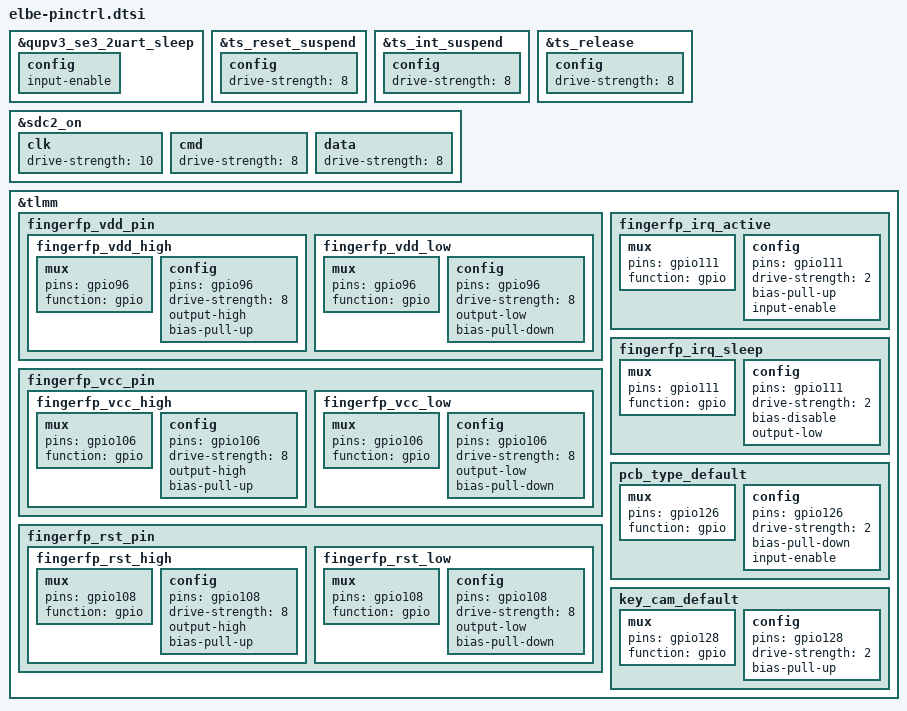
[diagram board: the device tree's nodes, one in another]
&qupv3_se3_2uart_sleep {
	config {
		input-enable;
	};
};

&ts_reset_suspend {
	config {
		drive-strength = <8>;
	};
};

&ts_int_suspend {
	config {
		drive-strength = <8>;
	};
};

&ts_release {
	config {
		drive-strength = <8>;
		/delete-property/ bias-disable;
	};
};

&sdc2_on {
	clk {
		drive-strength = <10>;
	};

	cmd {
		drive-strength = <8>;
	};

	data {
		drive-strength = <8>;
	};
};

&tlmm {
	fingerfp_vdd_pin: fingerfp_vdd_pin {
		fingerfp_vdd_high: fingerfp_vdd_high {
			mux {
				pins = "gpio96";
				function = "gpio";
			};

			config {
				pins = "gpio96";
				drive-strength = <8>;
				output-high;
				bias-pull-up;
			};
		};

		fingerfp_vdd_low: fingerfp_vdd_low {
			mux {
				pins = "gpio96";
				function = "gpio";
			};

			config {
				pins = "gpio96";
				drive-strength = <8>;
				output-low;
				bias-pull-down;
			};
		};
	};

	fingerfp_vcc_pin: fingerfp_vcc_pin {
		fingerfp_vcc_high: fingerfp_vcc_high {
			mux {
				pins = "gpio106";
				function = "gpio";
			};

			config {
				pins = "gpio106";
				drive-strength = <8>;
				output-high;
				bias-pull-up;
			};
		};

		fingerfp_vcc_low: fingerfp_vcc_low {
			mux {
				pins = "gpio106";
				function = "gpio";
			};

			config {
				pins = "gpio106";
				drive-strength = <8>;
				output-low;
				bias-pull-down;
			};
		};
	};

	fingerfp_rst_pin: fingerfp_rst_pin {
		fingerfp_rst_high: fingerfp_rst_high {
			mux {
				pins = "gpio108";
				function = "gpio";
			};

			config {
				pins = "gpio108";
				drive-strength = <8>;
				output-high;
				bias-pull-up;
			};
		};

		fingerfp_rst_low: fingerfp_rst_low {
			mux {
				pins = "gpio108";
				function = "gpio";
			};

			config {
				pins = "gpio108";
				drive-strength = <8>;
				output-low;
				bias-pull-down;
			};
		};
	};

	fingerfp_irq_active: fingerfp_irq_active {
		mux {
			pins = "gpio111";
			function = "gpio";
		};

		config {
			pins = "gpio111";
			drive-strength = <2>;
			bias-pull-up;
			input-enable;
		};
	};

	fingerfp_irq_sleep: fingerfp_irq_sleep {
		mux {
			pins = "gpio111";
			function = "gpio";
		};

		config {
			pins = "gpio111";
			drive-strength = <2>;
			bias-disable;
			output-low;
		};
	};

	pcb_type_default: pcb_type_default {
		mux {
			pins = "gpio126";
			function = "gpio";
		};

		config {
			pins = "gpio126";
			drive-strength = <2>;
			bias-pull-down;
			input-enable;
		};
	};

	key_cam_default: key_cam_default {
		mux {
			pins = "gpio128";
			function = "gpio";
		};

		config {
			pins = "gpio128";
			drive-strength = <2>;
			bias-pull-up;
		};
	};
};
